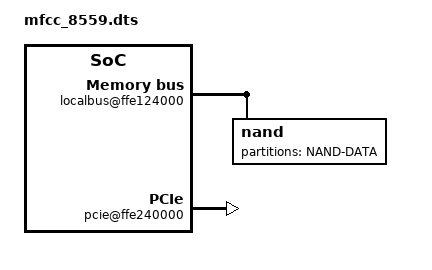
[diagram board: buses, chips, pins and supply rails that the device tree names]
/dts-v1/;

/include/ "mfcc_8559_eccp.dtsi"

/ {
	chosen {
		bootargs = "console=ttyS0,115200";

		/* reserve 256MB for rootfs */
		linux,initrd-start = <0x6c000000>;
		linux,initrd-end =   <0x7bffffff>;
	};

	localbus@ffe124000 {

		nand@1,0 {
			status = "okay";

			partition@0 {
				reg = <0 0x1000000>;
				label = "NAND-DATA";
			};
		};
	};

	pcie@ffe240000 {

		ranges = <
			/* PCIe0 I/O Space 0_0000_0000 -> 5_0000_0000 - 5_0000_ffff */
			0x01000000 0 0x00000000 5 0x00000000 0 0x00010000
			/* PCIe0 Mem Space 0_c000_0000 -> 3_0000_0000 - 3_3fff_ffff */
			0x02000000 0 0xc0000000 3 0x00000000 0 0x40000000
			/* PCIe0 Pref. Mem 1_0000_0000 -> 6_0000_0000 - 7_ffff_ffff */
			0x43000000 1 0x00000000 6 0x00000000 2 0x00000000
		>;

		status = "okay";

		dma-ranges = <0x43000000 0 0 0 0 0 0x7f000000>;

		pcie@0 {
			device_type = "pci";
			reg = <0 0 0 0 0>;
			#interrupt-cells = <1>;
			#size-cells = <2>;
			#address-cells = <3>;
			interrupts = <20 2 0 0>;
			interrupt-map-mask = <0xf800 0 0 7>;
			interrupt-map = <
				/* IDSEL 0x0 */
				0 0 0 1 &mpic 40 1 0 0
				0 0 0 2 &mpic  1 1 0 0
				0 0 0 3 &mpic  2 1 0 0
				0 0 0 4 &mpic  3 1 0 0
			>;
			ranges = <
				/* PCIe to PCIe transparent: I/O space */
				0x01000000 0 0x00000000 5 0x00000000 0 0x00010000
				/* PCIe to PCIe transparent: memory space */
				0x02000000 0 0xc0000000 3 0x00000000 0 0x40000000
				/* PCIe to PCIe transparent: prefetchable memory space */
				0x43000000 1 0x00000000 6 0x00000000 2 0x00000000
			>;
		};
	};
};
